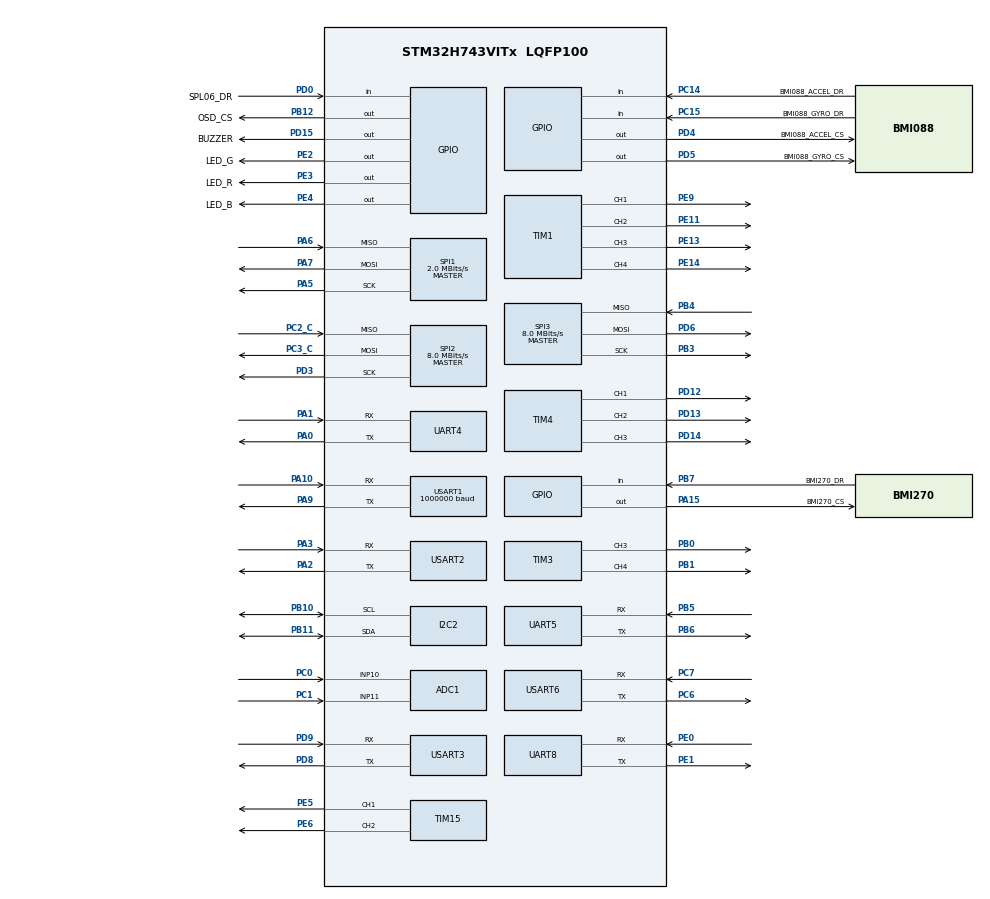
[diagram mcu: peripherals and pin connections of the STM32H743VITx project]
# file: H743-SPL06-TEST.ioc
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ADC1.Channel-0\#ChannelRegularConversion=ADC_CHANNEL_11
ADC1.NbrOfConversionFlag=1
ADC1.OffsetNumber-0\#ChannelRegularConversion=ADC_OFFSET_NONE
ADC1.OffsetSignedSaturation-0\#ChannelRegularConversion=DISABLE
ADC1.Rank-0\#ChannelRegularConversion=1
ADC1.SamplingTime-0\#ChannelRegularConversion=ADC_SAMPLETIME_1CYCLE_5
ADC1.master=1
CORTEX_M7.MPU_Control=__NULL
CORTEX_M7.default_mode_Activation=1
Dma.Request0=USART1_TX
Dma.USART1_TX.0.Direction=DMA_MEMORY_TO_PERIPH
Dma.USART1_TX.0.EventEnable=DISABLE
Dma.USART1_TX.0.FIFOMode=DMA_FIFOMODE_DISABLE
Dma.USART1_TX.0.Instance=DMA1_Stream0
Dma.USART1_TX.0.MemDataAlignment=DMA_MDATAALIGN_BYTE
Dma.USART1_TX.0.MemInc=DMA_MINC_ENABLE
Dma.USART1_TX.0.Mode=DMA_NORMAL
Dma.USART1_TX.0.PeriphDataAlignment=DMA_PDATAALIGN_BYTE
Dma.USART1_TX.0.PeriphInc=DMA_PINC_DISABLE
Dma.USART1_TX.0.Polarity=HAL_DMAMUX_REQ_GEN_RISING
Dma.USART1_TX.0.Priority=DMA_PRIORITY_MEDIUM
Dma.USART1_TX.0.RequestNumber=1
Dma.USART1_TX.0.SignalID=NONE
Dma.USART1_TX.0.SyncEnable=DISABLE
Dma.USART1_TX.0.SyncPolarity=HAL_DMAMUX_SYNC_NO_EVENT
Dma.USART1_TX.0.SyncRequestNumber=1
Dma.USART1_TX.0.SyncSignalID=NONE
I2C2.Timing=0x307075B1
Mcu.Family=STM32H7
Mcu.Name=STM32H743VITx
Mcu.Package=LQFP100
NVIC.DMA1_Stream0_IRQn=true\:0\:0\:false\:false\:true\:false\:true\:true
NVIC.PriorityGroup=NVIC_PRIORITYGROUP_4
NVIC.USART1_IRQn=true\:0\:0\:false\:false\:true\:true\:true\:true
PA0.Mode=Asynchronous
PA0.Signal=UART4_TX
PA1.Mode=Asynchronous
PA1.Signal=UART4_RX
PA10.Mode=Asynchronous
PA10.Signal=USART1_RX
PA13\ (JTMS/SWDIO).Mode=Serial_Wire
PA13\ (JTMS/SWDIO).Signal=DEBUG_JTMS-SWDIO
PA14\ (JTCK/SWCLK).Mode=Serial_Wire
PA14\ (JTCK/SWCLK).Signal=DEBUG_JTCK-SWCLK
PA15\ (JTDI).GPIO_Label=BMI270_CS
PA15\ (JTDI).GPIO_Speed=GPIO_SPEED_FREQ_VERY_HIGH
PA15\ (JTDI).PinState=GPIO_PIN_SET
PA15\ (JTDI).Signal=GPIO_Output
PA2.Mode=Asynchronous
PA2.Signal=USART2_TX
PA3.Mode=Asynchronous
PA3.Signal=USART2_RX
PA5.Mode=Full_Duplex_Master
PA5.Signal=SPI1_SCK
PA6.Mode=Full_Duplex_Master
PA6.Signal=SPI1_MISO
PA7.Mode=Full_Duplex_Master
PA7.Signal=SPI1_MOSI
PA9.Mode=Asynchronous
PA9.Signal=USART1_TX
PB0.Signal=S_TIM3_CH3
PB1.Signal=S_TIM3_CH4
PB10.Mode=I2C
PB10.Signal=I2C2_SCL
PB11.Mode=I2C
PB11.Signal=I2C2_SDA
PB12.GPIO_Label=OSD_CS
PB12.GPIO_PuPd=GPIO_NOPULL
PB12.GPIO_Speed=GPIO_SPEED_FREQ_VERY_HIGH
PB12.PinState=GPIO_PIN_SET
PB12.Signal=GPIO_Output
PB3\ (JTDO/TRACESWO).Mode=Full_Duplex_Master
PB3\ (JTDO/TRACESWO).Signal=SPI3_SCK
PB4\ (NJTRST).Mode=Full_Duplex_Master
PB4\ (NJTRST).Signal=SPI3_MISO
PB5.Mode=Asynchronous
PB5.Signal=UART5_RX
PB6.Mode=Asynchronous
PB6.Signal=UART5_TX
PB7.GPIO_Label=BMI270_DR
PB7.Signal=GPIO_Input
PC0.Signal=ADCx_INP10
PC1.Signal=ADCx_INP11
PC14-OSC32_IN\ (OSC32_IN).GPIO_Label=BMI088_ACCEL_DR
PC14-OSC32_IN\ (OSC32_IN).Signal=GPIO_Input
PC15-OSC32_OUT\ (OSC32_OUT).GPIO_Label=BMI088_GYRO_DR
PC15-OSC32_OUT\ (OSC32_OUT).Signal=GPIO_Input
PC2_C.Mode=Full_Duplex_Master
PC2_C.Signal=SPI2_MISO
PC3_C.Mode=Full_Duplex_Master
PC3_C.Signal=SPI2_MOSI
PC6.Mode=Asynchronous
PC6.Signal=USART6_TX
PC7.Mode=Asynchronous
PC7.Signal=USART6_RX
PD0.GPIO_Label=SPL06_DR
PD0.Signal=GPIO_Input
PD12.Signal=S_TIM4_CH1
PD13.Signal=S_TIM4_CH2
PD14.Signal=S_TIM4_CH3
PD15.GPIO_Label=BUZZER
PD15.Signal=GPIO_Output
PD3.Mode=Full_Duplex_Master
PD3.Signal=SPI2_SCK
PD4.GPIO_Label=BMI088_ACCEL_CS
PD4.GPIO_Speed=GPIO_SPEED_FREQ_VERY_HIGH
PD4.PinState=GPIO_PIN_SET
PD4.Signal=GPIO_Output
PD5.GPIO_Label=BMI088_GYRO_CS
PD5.GPIO_PuPd=GPIO_NOPULL
PD5.GPIO_Speed=GPIO_SPEED_FREQ_VERY_HIGH
PD5.PinState=GPIO_PIN_SET
PD5.Signal=GPIO_Output
PD6.Mode=Full_Duplex_Master
PD6.Signal=SPI3_MOSI
PD8.Mode=Asynchronous
PD8.Signal=USART3_TX
PD9.Mode=Asynchronous
PD9.Signal=USART3_RX
PE0.Mode=Asynchronous
PE0.Signal=UART8_RX
PE1.Mode=Asynchronous
PE1.Signal=UART8_TX
PE11.Signal=S_TIM1_CH2
PE13.Signal=S_TIM1_CH3
PE14.Signal=S_TIM1_CH4
PE2.GPIO_Label=LED_G
PE2.GPIO_Speed=GPIO_SPEED_FREQ_VERY_HIGH
PE2.PinState=GPIO_PIN_SET
PE2.Signal=GPIO_Output
PE3.GPIO_Label=LED_R
PE3.GPIO_Speed=GPIO_SPEED_FREQ_VERY_HIGH
PE3.PinState=GPIO_PIN_SET
PE3.Signal=GPIO_Output
PE4.GPIO_Label=LED_B
PE4.GPIO_Speed=GPIO_SPEED_FREQ_VERY_HIGH
PE4.PinState=GPIO_PIN_SET
PE4.Signal=GPIO_Output
PE5.Signal=S_TIM15_CH1
PE6.Signal=S_TIM15_CH2
PE9.Signal=S_TIM1_CH1
PH0-OSC_IN\ (PH0).Mode=HSE-External-Oscillator
PH0-OSC_IN\ (PH0).Signal=RCC_OSC_IN
PH1-OSC_OUT\ (PH1).Mode=HSE-External-Oscillator
PH1-OSC_OUT\ (PH1).Signal=RCC_OSC_OUT
ProjectManager.HeapSize=0x200
ProjectManager.StackSize=0x400
ProjectManager.TargetToolchain=MDK-ARM V5.32
RCC.ADCFreq_Value=75000000
RCC.APB1Freq_Value=120000000
RCC.APB2Freq_Value=120000000
RCC.APB3Freq_Value=120000000
RCC.APB4Freq_Value=120000000
RCC.CortexFreq_Value=480000000
RCC.D1PPRE=RCC_APB3_DIV2
RCC.D2PPRE1=RCC_APB1_DIV2
RCC.D2PPRE2=RCC_APB2_DIV2
RCC.D3PPRE=RCC_APB4_DIV2
RCC.DIVM1=1
RCC.DIVM2=1
RCC.DIVN1=120
RCC.DIVN2=18
RCC.DIVQ1=15
RCC.HCLKFreq_Value=240000000
RCC.HPRE=RCC_HCLK_DIV2
RCC.HSE_VALUE=8000000
RCC.PLL2FRACN=6144
RCC.PLL3FRACN=0
RCC.PLLFRACN=0
RCC.PLLSourceVirtual=RCC_PLLSOURCE_HSE
RCC.SYSCLKFreq_VALUE=480000000
RCC.SYSCLKSource=RCC_SYSCLKSOURCE_PLLCLK
RCC.USBFreq_Value=64000000
SH.ADCx_INP10.0=ADC1_INP10,IN10-Single-Ended
SH.ADCx_INP11.0=ADC1_INP11,IN11-Single-Ended
SH.S_TIM15_CH1.0=TIM15_CH1,PWM Generation1 CH1
SH.S_TIM15_CH2.0=TIM15_CH2,PWM Generation2 CH2
SH.S_TIM1_CH1.0=TIM1_CH1,PWM Generation1 CH1
SH.S_TIM1_CH2.0=TIM1_CH2,PWM Generation2 CH2
SH.S_TIM1_CH3.0=TIM1_CH3,PWM Generation3 CH3
SH.S_TIM1_CH4.0=TIM1_CH4,PWM Generation4 CH4
SH.S_TIM3_CH3.0=TIM3_CH3,PWM Generation3 CH3
SH.S_TIM3_CH4.0=TIM3_CH4,PWM Generation4 CH4
SH.S_TIM4_CH1.0=TIM4_CH1,PWM Generation1 CH1
SH.S_TIM4_CH2.0=TIM4_CH2,PWM Generation2 CH2
SH.S_TIM4_CH3.0=TIM4_CH3,PWM Generation3 CH3
SPI1.BaudRatePrescaler=SPI_BAUDRATEPRESCALER_32
SPI1.CalculateBaudRate=2.0 MBits/s
SPI1.DataSize=SPI_DATASIZE_8BIT
SPI1.Direction=SPI_DIRECTION_2LINES
SPI1.Mode=SPI_MODE_MASTER
SPI1.VirtualType=VM_MASTER
SPI2.BaudRatePrescaler=SPI_BAUDRATEPRESCALER_8
SPI2.CLKPhase=SPI_PHASE_2EDGE
SPI2.CLKPolarity=SPI_POLARITY_HIGH
SPI2.CalculateBaudRate=8.0 MBits/s
SPI2.DataSize=SPI_DATASIZE_8BIT
SPI2.Direction=SPI_DIRECTION_2LINES
SPI2.Mode=SPI_MODE_MASTER
SPI2.VirtualType=VM_MASTER
SPI3.BaudRatePrescaler=SPI_BAUDRATEPRESCALER_8
SPI3.CLKPhase=SPI_PHASE_2EDGE
SPI3.CLKPolarity=SPI_POLARITY_HIGH
SPI3.CalculateBaudRate=8.0 MBits/s
SPI3.DataSize=SPI_DATASIZE_8BIT
SPI3.Direction=SPI_DIRECTION_2LINES
SPI3.Mode=SPI_MODE_MASTER
SPI3.VirtualType=VM_MASTER
TIM1.Channel-PWM\ Generation1\ CH1=TIM_CHANNEL_1
TIM1.Channel-PWM\ Generation2\ CH2=TIM_CHANNEL_2
TIM1.Channel-PWM\ Generation3\ CH3=TIM_CHANNEL_3
TIM1.Channel-PWM\ Generation4\ CH4=TIM_CHANNEL_4
TIM15.Channel-PWM\ Generation1\ CH1=TIM_CHANNEL_1
TIM15.Channel-PWM\ Generation2\ CH2=TIM_CHANNEL_2
TIM3.Channel-PWM\ Generation3\ CH3=TIM_CHANNEL_3
TIM3.Channel-PWM\ Generation4\ CH4=TIM_CHANNEL_4
TIM4.Channel-PWM\ Generation1\ CH1=TIM_CHANNEL_1
TIM4.Channel-PWM\ Generation2\ CH2=TIM_CHANNEL_2
TIM4.Channel-PWM\ Generation3\ CH3=TIM_CHANNEL_3
USART1.BaudRate=1000000
USART1.VirtualMode-Asynchronous=VM_ASYNC
USART2.VirtualMode-Asynchronous=VM_ASYNC
USART3.VirtualMode-Asynchronous=VM_ASYNC
USART6.VirtualMode=VM_ASYNC
VP_TIM15_VS_ClockSourceINT.Mode=Internal
VP_TIM1_VS_ClockSourceINT.Mode=Internal
VP_TIM3_VS_ClockSourceINT.Mode=Internal
VP_TIM4_VS_ClockSourceINT.Mode=Internal
board=custom

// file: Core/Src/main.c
/* USER CODE BEGIN Header */
/**
  ******************************************************************************
  * @file           : main.c
  * @brief          : Main program body
  ******************************************************************************
  * @attention
  *
  * Copyright (c) 2025 STMicroelectronics.
  * All rights reserved.
  *
  * This software is licensed under terms that can be found in the LICENSE file
  * in the root directory of this software component.
  * If no LICENSE file comes with this software, it is provided AS-IS.
  *
  ******************************************************************************
  */
/* USER CODE END Header */
#include "main.h"
#include "adc.h"
#include "dma.h"
#include "i2c.h"
#include "spi.h"
#include "tim.h"
#include "usart.h"
#include "gpio.h"

/* USER CODE BEGIN Includes */
#include "system.h"

/* USER CODE END Includes */

void SystemClock_Config(void);

int main(void)
{

  /* MCU Configuration--------------------------------------------------------*/

  /* Reset of all peripherals, Initializes the Flash interface and the Systick. */
  HAL_Init();

  /* Configure the system clock */
  SystemClock_Config();

  /* Initialize all configured peripherals */
  MX_GPIO_Init();
  MX_DMA_Init();
  MX_I2C2_Init();
  MX_SPI1_Init();
  MX_SPI2_Init();
  MX_SPI3_Init();
  MX_TIM1_Init();
  MX_TIM3_Init();
  MX_TIM4_Init();
  MX_TIM15_Init();
  MX_UART4_Init();
  MX_UART5_Init();
  MX_UART8_Init();
  MX_USART1_UART_Init();
  MX_USART2_UART_Init();
  MX_USART3_UART_Init();
  MX_USART6_UART_Init();
  MX_ADC1_Init();
  /* USER CODE BEGIN 2 */
  systemInit();
  /* USER CODE END 2 */

  /* Infinite loop */
  while (1)
  {

    /* USER CODE BEGIN 3 */
    systemLoop();
  }
  /* USER CODE END 3 */
}

void SystemClock_Config(void)
{
  RCC_OscInitTypeDef RCC_OscInitStruct = {0};
  RCC_ClkInitTypeDef RCC_ClkInitStruct = {0};

  /** Supply configuration update enable
  */
  HAL_PWREx_ConfigSupply(PWR_LDO_SUPPLY);

  /** Configure the main internal regulator output voltage
  */
  __HAL_PWR_VOLTAGESCALING_CONFIG(PWR_REGULATOR_VOLTAGE_SCALE1);

  while(!__HAL_PWR_GET_FLAG(PWR_FLAG_VOSRDY)) {}

  __HAL_RCC_SYSCFG_CLK_ENABLE();
  __HAL_PWR_VOLTAGESCALING_CONFIG(PWR_REGULATOR_VOLTAGE_SCALE0);

  while(!__HAL_PWR_GET_FLAG(PWR_FLAG_VOSRDY)) {}

  /** Initializes the RCC Oscillators according to the specified parameters
  * in the RCC_OscInitTypeDef structure.
  */
  RCC_OscInitStruct.OscillatorType = RCC_OSCILLATORTYPE_HSE;
  RCC_OscInitStruct.HSEState = RCC_HSE_ON;
  RCC_OscInitStruct.PLL.PLLState = RCC_PLL_ON;
  RCC_OscInitStruct.PLL.PLLSource = RCC_PLLSOURCE_HSE;
  RCC_OscInitStruct.PLL.PLLM = 1;
  RCC_OscInitStruct.PLL.PLLN = 120;
  RCC_OscInitStruct.PLL.PLLP = 2;
  RCC_OscInitStruct.PLL.PLLQ = 15;
  RCC_OscInitStruct.PLL.PLLR = 2;
  RCC_OscInitStruct.PLL.PLLRGE = RCC_PLL1VCIRANGE_3;
  RCC_OscInitStruct.PLL.PLLVCOSEL = RCC_PLL1VCOWIDE;
  RCC_OscInitStruct.PLL.PLLFRACN = 0;
  if (HAL_RCC_OscConfig(&RCC_OscInitStruct) != HAL_OK)
  {
    Error_Handler();
  }

  /** Initializes the CPU, AHB and APB buses clocks
  */
  RCC_ClkInitStruct.ClockType = RCC_CLOCKTYPE_HCLK|RCC_CLOCKTYPE_SYSCLK
                              |RCC_CLOCKTYPE_PCLK1|RCC_CLOCKTYPE_PCLK2
                              |RCC_CLOCKTYPE_D3PCLK1|RCC_CLOCKTYPE_D1PCLK1;
  RCC_ClkInitStruct.SYSCLKSource = RCC_SYSCLKSOURCE_PLLCLK;
  RCC_ClkInitStruct.SYSCLKDivider = RCC_SYSCLK_DIV1;
  RCC_ClkInitStruct.AHBCLKDivider = RCC_HCLK_DIV2;
  RCC_ClkInitStruct.APB3CLKDivider = RCC_APB3_DIV2;
  RCC_ClkInitStruct.APB1CLKDivider = RCC_APB1_DIV2;
  RCC_ClkInitStruct.APB2CLKDivider = RCC_APB2_DIV2;
  RCC_ClkInitStruct.APB4CLKDivider = RCC_APB4_DIV2;

  if (HAL_RCC_ClockConfig(&RCC_ClkInitStruct, FLASH_LATENCY_4) != HAL_OK)
  {
    Error_Handler();
  }
}

void Error_Handler(void)
{
  __disable_irq();
  while (1)
  {
  }
}
